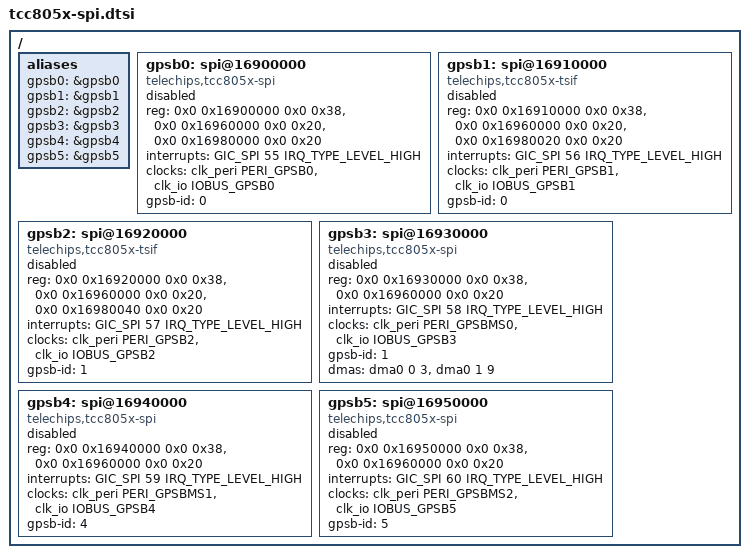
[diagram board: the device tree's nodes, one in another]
// SPDX-License-Identifier: (GPL-2.0-or-later OR MIT)
/*
 * Copyright (C) 2023 Telechips Inc.
 */

#include <dt-bindings/clock/telechips,tcc805x-clks.h>
#include <dt-bindings/interrupt-controller/arm-gic.h>

/ {
	aliases: aliases {
		gpsb0 = &gpsb0;
		gpsb1 = &gpsb1;
		gpsb2 = &gpsb2;
		gpsb3 = &gpsb3;
		gpsb4 = &gpsb4;
		gpsb5 = &gpsb5;
	};

	gpsb0: spi@16900000 {
		compatible = "telechips,tcc805x-spi";
		reg = <0x0 0x16900000 0x0 0x38>, /* base address */
		      <0x0 0x16960000 0x0 0x20>, /* Port Configuration register */
		      <0x0 0x16980000 0x0 0x20>; /* GPSB_0_AC */
		interrupts = <GIC_SPI 55 IRQ_TYPE_LEVEL_HIGH>;
		clocks = <&clk_peri PERI_GPSB0 &clk_io IOBUS_GPSB0>;
		gpsb-id = <0>;
		status = "disabled";
	};

	gpsb1: spi@16910000 {
		compatible = "telechips,tcc805x-tsif";
		reg = <0x0 0x16910000 0x0 0x38>, /* base address */
		      <0x0 0x16960000 0x0 0x20>, /* Port Configuration register */
		      <0x0 0x16980020 0x0 0x20>; /* GPSB_1_AC */
		interrupts = <GIC_SPI 56 IRQ_TYPE_LEVEL_HIGH>;
		clocks = <&clk_peri PERI_GPSB1 &clk_io IOBUS_GPSB1>;
		gpsb-id = <0>;
		status = "disabled";
	};

	gpsb2: spi@16920000 {
		compatible = "telechips,tcc805x-tsif";
		reg = <0x0 0x16920000 0x0 0x38>, /* base address */
		      <0x0 0x16960000 0x0 0x20>, /* Port Configuration register */
		      <0x0 0x16980040 0x0 0x20>; /* GPSB_2_AC */
		interrupts = <GIC_SPI 57 IRQ_TYPE_LEVEL_HIGH>;
		clocks = <&clk_peri PERI_GPSB2 &clk_io IOBUS_GPSB2>;
		gpsb-id = <1>;
		status = "disabled";
	};

	gpsb3: spi@16930000 {
		compatible = "telechips,tcc805x-spi";
		reg = <0x0 0x16930000 0x0 0x38>, /* base address */
		      <0x0 0x16960000 0x0 0x20>; /* Port Configuration register */
		interrupts = <GIC_SPI 58 IRQ_TYPE_LEVEL_HIGH>;
		clocks = <&clk_peri PERI_GPSBMS0 &clk_io IOBUS_GPSB3>;
		gpsb-id = <1>;
		status = "disabled";

		// With DMA-engine
		dmas = <&dma0 0 3 &dma0 1 9>;
		dma-names = "tx", "rx";
	};

	gpsb4: spi@16940000 {
		compatible = "telechips,tcc805x-spi";
		reg = <0x0 0x16940000 0x0 0x38>, /* base address */
		      <0x0 0x16960000 0x0 0x20>; /* Port Configuration register */
		interrupts = <GIC_SPI 59 IRQ_TYPE_LEVEL_HIGH>;
		clocks = <&clk_peri PERI_GPSBMS1 &clk_io IOBUS_GPSB4>;
		gpsb-id = <4>;
		status = "disabled";

		// With DMA-engine
		//dmas = <&dma0 0 4 &dma0 1 10>;
		//dma-names = "tx", "rx";
	};

	gpsb5: spi@16950000 {
		compatible = "telechips,tcc805x-spi";
		reg = <0x0 0x16950000 0x0 0x38>, /* base address */
		      <0x0 0x16960000 0x0 0x20>; /* Port Configuration register */
		interrupts = <GIC_SPI 60 IRQ_TYPE_LEVEL_HIGH>;
		clocks = <&clk_peri PERI_GPSBMS2 &clk_io IOBUS_GPSB5>;
		gpsb-id = <5>;
		status = "disabled";

		// With DMA-engine
		//dmas = <&dma0 0 5 &dma0 1 11>;
		//dma-names = "tx", "rx";
	};
};
